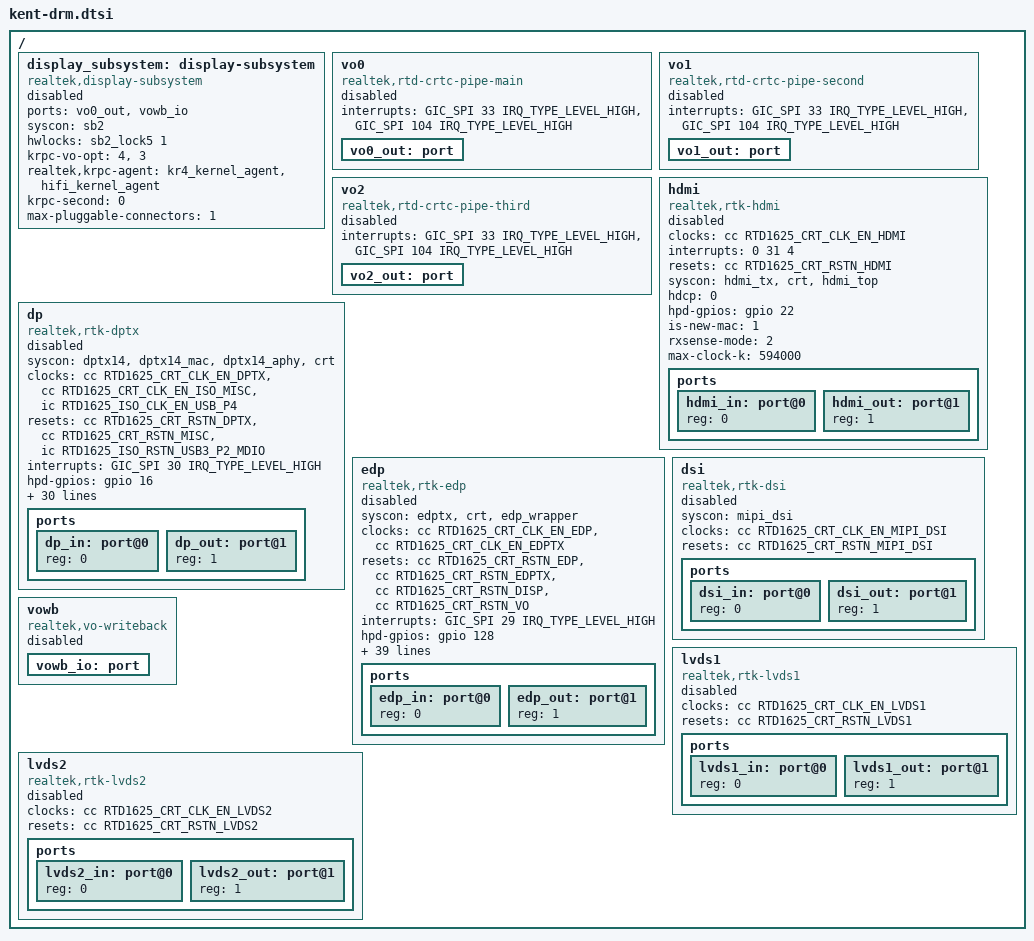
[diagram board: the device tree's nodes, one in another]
// SPDX-License-Identifier: (GPL-2.0-or-later OR BSD-2-Clause)
/*
 * Copyright (c) 2024 Realtek Semiconductor Corp.
 */

/* PLEASE include this file inside a node */
/ {
	display_subsystem: display-subsystem {
		compatible = "realtek,display-subsystem";
		ports = <&vo0_out>, <&vowb_io>;
		syscon = <&sb2>;
		hwlocks = <&sb2_lock5 1>;
		krpc-vo-opt = <4>, <3>;
		realtek,krpc-agent = <&kr4_kernel_agent>, <&hifi_kernel_agent>;
		krpc-second = <0>;
		max-pluggable-connectors = <1>;
		status = "disabled";
	};

	vo0: vo0 {
		compatible = "realtek,rtd-crtc-pipe-main";
		interrupts = <GIC_SPI 33 IRQ_TYPE_LEVEL_HIGH>,
					<GIC_SPI 104 IRQ_TYPE_LEVEL_HIGH>;
		status = "disabled";

		vo0_out: port {
		};
	};

	vo1: vo1 {
		compatible = "realtek,rtd-crtc-pipe-second";
		interrupts = <GIC_SPI 33 IRQ_TYPE_LEVEL_HIGH>,
					<GIC_SPI 104 IRQ_TYPE_LEVEL_HIGH>;
		status = "disabled";

		vo1_out: port {
		};
	};

	vo2: vo2 {
		compatible = "realtek,rtd-crtc-pipe-third";
		interrupts = <GIC_SPI 33 IRQ_TYPE_LEVEL_HIGH>,
					<GIC_SPI 104 IRQ_TYPE_LEVEL_HIGH>;
		status = "disabled";

		vo2_out: port {
		};
	};

	hdmi: hdmi {
		compatible = "realtek,rtk-hdmi";
		clock-names = "clk_en_hdmi";
		clocks = <&cc RTD1625_CRT_CLK_EN_HDMI>;
		interrupts = <0 31 4>; /* RxSense */
		reset-names = "rstn_hdmi";
		resets = <&cc RTD1625_CRT_RSTN_HDMI>;
		syscon = <&hdmi_tx>, <&crt>, <&hdmi_top>;
		hdcp = <0>;
		hpd-gpios = <&gpio 22 GPIO_PULL_DOWN>;
		is-new-mac = <1>;
		rxsense-mode = <2>;
		max-clock-k = <594000>;
		status = "disabled";

		ports {
			#address-cells = <1>;
			#size-cells = <0>;

			hdmi_in: port@0 {
				reg = <0>;
			};

			hdmi_out: port@1 {
				reg = <1>;
			};
		};
	};

	dp: dp {
		compatible = "realtek,rtk-dptx";
		syscon = <&dptx14>, <&dptx14_mac>, <&dptx14_aphy>, <&crt>;
		clock-names = "clk_en_dptx",
					"clk_iso_misc",
					"clk_usb_p4";
		clocks = <&cc RTD1625_CRT_CLK_EN_DPTX>,
				<&cc RTD1625_CRT_CLK_EN_ISO_MISC>,
				<&ic RTD1625_ISO_CLK_EN_USB_P4>;
		reset-names = "rstn_dptx",
					"rstn_misc",
					"rstn_u3_mdio";
		resets = <&cc RTD1625_CRT_RSTN_DPTX>,
				<&cc RTD1625_CRT_RSTN_MISC>,
				<&ic RTD1625_ISO_RSTN_USB3_P2_MDIO>;
		interrupts = <GIC_SPI 30 IRQ_TYPE_LEVEL_HIGH>;
		hpd-gpios = <&gpio 16 GPIO_ACTIVE_HIGH>;
		realtek,pinctrl = <&ve4_pinctrl>;
		max-clock-k = <594000>;
		status = "disabled";
		normal-lane-table = <2 3 0 1>;
		flipped-lane-table = <1 0 3 2>;
		hbr-rbr-sw-emp-table =
			<0x1 0x0 0x5 0x0>, <0x1 0x0 0x2 0x4>, <0x1 0x1 0x1 0x8>, <0x1 0x2 0x0 0xc>,
			<0x1 0x2 0x3 0x1>, <0x1 0x3 0x0 0x7>, <0x1 0x4 0x0 0xa>, <0x0 0x0 0x0 0x0>,
			<0x1 0x5 0x3 0x1>, <0x1 0x7 0x0 0x9>, <0x0 0x0 0x0 0x0>, <0x0 0x0 0x0 0x0>,
			<0x1 0x7 0x1 0x0>, <0x0 0x0 0x0 0x0>, <0x0 0x0 0x0 0x0>, <0x0 0x0 0x0 0x0>;
		hbr2-hbr3-sw-emp-table =
			<0x1 0x0 0x4 0x1>, <0x1 0x0 0x2 0x5>, <0x1 0x1 0x1 0x8>, <0x1 0x2 0x0 0xb>,
			<0x1 0x2 0x3 0x1>, <0x1 0x3 0x0 0x7>, <0x1 0x4 0x0 0xa>, <0x0 0x0 0x0 0x0>,
			<0x1 0x5 0x3 0x1>, <0x1 0x7 0x0 0x9>, <0x0 0x0 0x0 0x0>, <0x0 0x0 0x0 0x0>,
			<0x1 0x7 0x1 0x0>, <0x0 0x0 0x0 0x0>, <0x0 0x0 0x0 0x0>, <0x0 0x0 0x0 0x0>;
		drv-table =
			<0x00 0x00 0x03>, <0x00 0x07 0x05>, <0x00 0x0C 0x05>, <0x01 0x09 0x06>,
			<0x00 0x00 0x05>, <0x00 0x07 0x05>, <0x00 0x0C 0x05>, <0x00 0x0C 0x05>,
			<0x00 0x00 0x09>, <0x00 0x0C 0x09>, <0x00 0x0C 0x09>, <0x00 0x0C 0x09>,
			<0x00 0x00 0x0E>, <0x00 0x00 0x0E>, <0x00 0x00 0x0E>, <0x00 0x00 0x0E>;
		ports {
			#address-cells = <1>;
			#size-cells = <0>;

			dp_in: port@0 {
				reg = <0>;
			};

			dp_out: port@1 {
				reg = <1>;
			};
		};
	};

	edp: edp {
		compatible = "realtek,rtk-edp";
		syscon = <&edptx>, <&crt>, <&edp_wrapper>;
		clock-names = "clk_en_edp", "clk_en_edptx";
		clocks = <&cc RTD1625_CRT_CLK_EN_EDP>,
				<&cc RTD1625_CRT_CLK_EN_EDPTX>;
		reset-names = "rstn_edp",
					"rstn_edptx",
					"rstn_disp",
					"rstn_vo";
		resets = <&cc RTD1625_CRT_RSTN_EDP>,
				<&cc RTD1625_CRT_RSTN_EDPTX>,
				<&cc RTD1625_CRT_RSTN_DISP>,
				<&cc RTD1625_CRT_RSTN_VO>;
		interrupts = <GIC_SPI 29 IRQ_TYPE_LEVEL_HIGH>;
		hpd-gpios = <&gpio 128 GPIO_ACTIVE_HIGH>;
		realtek,pinctrl = <&iso_pinctrl>;
		realtek,iso = <&iso>;
		assr-en = <0>;
		max-clock-k = <348500>;
		status = "disabled";
		rbr-sw-emp-table =
			<0x0 0x34 0x00 0x7>, <0x1 0x00 0x0b 0x7>, <0x1 0x14 0x1E 0x7>, <0x1 0x38 0x38 0xf>,
			<0x1 0x11 0x00 0x7>, <0x1 0x17 0x18 0x7>, <0x1 0x38 0x18 0xf>, <0x0 0x00 0x00 0x0>,
			<0x1 0x2D 0x00 0x7>, <0x1 0x3c 0x18 0xf>, <0x0 0x00 0x00 0x0>, <0x0 0x00 0x00 0x0>,
			<0x1 0x3f 0x00 0xf>, <0x0 0x00 0x00 0x0>, <0x0 0x00 0x00 0x0>, <0x0 0x00 0x00 0x0>;
		hbr-sw-emp-table =
			<0x0 0x30 0x00 0x7>, <0x1 0x00 0x17 0x7>, <0x1 0x17 0x24 0x7>, <0x1 0x3c 0x38 0xf>,
			<0x1 0x08 0x00 0x7>, <0x1 0x10 0x18 0x7>, <0x1 0x3e 0x14 0xf>, <0x0 0x00 0x00 0x0>,
			<0x1 0x1c 0x00 0x7>, <0x1 0x3f 0x16 0xf>, <0x0 0x00 0x00 0x0>, <0x0 0x00 0x00 0x0>,
			<0x1 0x3c 0x00 0xf>, <0x0 0x00 0x00 0x0>, <0x0 0x00 0x00 0x0>, <0x0 0x00 0x00 0x0>;
		hbr2-sw-emp-table =
			<0x0 0x30 0x00 0x7>, <0x1 0x10 0x20 0x7>, <0x1 0x38 0x39 0x7>, <0x1 0x3f 0x20 0xf>,
			<0x1 0x0c 0x00 0x7>, <0x1 0x18 0x20 0xf>, <0x1 0x3f 0x10 0xf>, <0x0 0x00 0x00 0x0>,
			<0x1 0x14 0x00 0x7>, <0x1 0x3f 0x20 0xf>, <0x0 0x00 0x00 0x0>, <0x0 0x00 0x00 0x0>,
			<0x1 0x3f 0x00 0xf>, <0x0 0x00 0x00 0x0>, <0x0 0x00 0x00 0x0>, <0x0 0x00 0x00 0x0>;
		drv-table =
			<0x00 0x00 0x03>, <0x00 0x07 0x05>, <0x00 0x0C 0x05>, <0x01 0x09 0x06>,
			<0x00 0x00 0x05>, <0x00 0x07 0x05>, <0x00 0x0C 0x05>, <0x00 0x0C 0x05>,
			<0x00 0x00 0x09>, <0x00 0x0C 0x09>, <0x00 0x0C 0x09>, <0x00 0x0C 0x09>,
			<0x00 0x00 0x0E>, <0x00 0x00 0x0E>, <0x00 0x00 0x0E>, <0x00 0x00 0x0E>;

		ports {
			#address-cells = <1>;
			#size-cells = <0>;

			edp_in: port@0 {
				reg = <0>;
			};

			edp_out: port@1 {
				reg = <1>;
			};
		};
	};

	dsi: dsi {
		compatible = "realtek,rtk-dsi";
		syscon = <&mipi_dsi>;
		clocks = <&cc RTD1625_CRT_CLK_EN_MIPI_DSI>;
		clock-names = "clk_en_dsi";
		resets = <&cc RTD1625_CRT_RSTN_MIPI_DSI>;
		reset-names = "dsi";
		status = "disabled";

		ports {
			#address-cells = <1>;
			#size-cells = <0>;

			dsi_in: port@0 {
				reg = <0>;
			};

			dsi_out: port@1 {
				reg = <1>;
			};
		};
	};

	vowb: vowb {
		compatible = "realtek,vo-writeback";
		status = "disabled";
		vowb_io: port {
		};
	};

	lvds1: lvds1 {
		compatible = "realtek,rtk-lvds1";
		clock-names = "clk_en_lvds1";
		clocks = <&cc RTD1625_CRT_CLK_EN_LVDS1>;
		reset-names = "rstn_lvds1";
		resets = <&cc RTD1625_CRT_RSTN_LVDS1>;

		status = "disabled";

		ports {
			#address-cells = <1>;
			#size-cells = <0>;

			lvds1_in: port@0 {
				reg = <0>;
			};

			lvds1_out: port@1 {
				reg = <1>;
			};
		};
	};

	lvds2: lvds2 {
		compatible = "realtek,rtk-lvds2";
		clock-names = "clk_en_lvds2";
		clocks = <&cc RTD1625_CRT_CLK_EN_LVDS2>;
		reset-names = "rstn_lvds2";
		resets = <&cc RTD1625_CRT_RSTN_LVDS2>;

		status = "disabled";

		ports {
			#address-cells = <1>;
			#size-cells = <0>;

			lvds2_in: port@0 {
				reg = <0>;
			};

			lvds2_out: port@1 {
				reg = <1>;
			};
		};
	};
};
